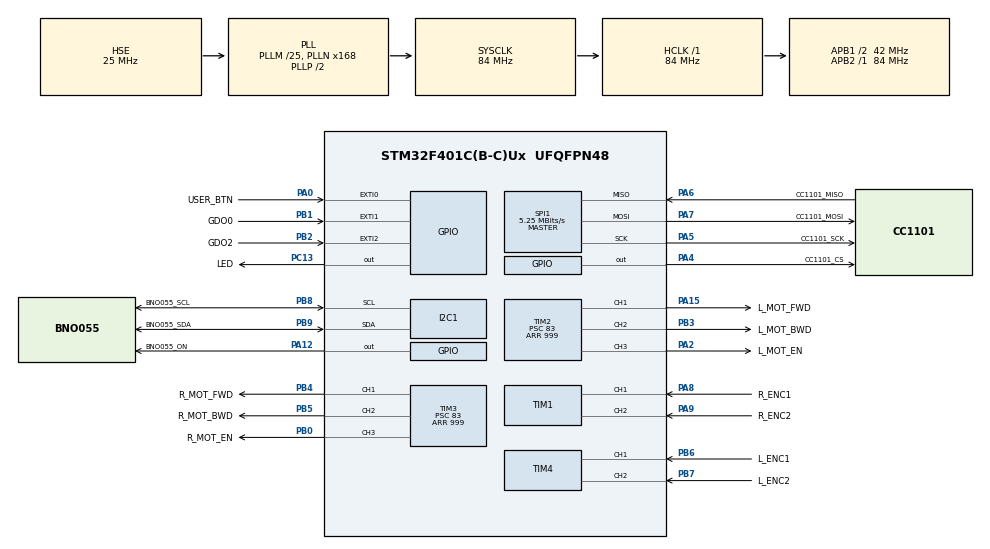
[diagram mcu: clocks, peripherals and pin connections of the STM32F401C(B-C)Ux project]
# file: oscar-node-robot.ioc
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Dma.Request0=SPI1_RX
Dma.Request1=SPI1_TX
Dma.SPI1_RX.0.Direction=DMA_PERIPH_TO_MEMORY
Dma.SPI1_RX.0.FIFOMode=DMA_FIFOMODE_DISABLE
Dma.SPI1_RX.0.Instance=DMA2_Stream0
Dma.SPI1_RX.0.MemDataAlignment=DMA_MDATAALIGN_BYTE
Dma.SPI1_RX.0.MemInc=DMA_MINC_ENABLE
Dma.SPI1_RX.0.Mode=DMA_NORMAL
Dma.SPI1_RX.0.PeriphDataAlignment=DMA_PDATAALIGN_BYTE
Dma.SPI1_RX.0.PeriphInc=DMA_PINC_DISABLE
Dma.SPI1_RX.0.Priority=DMA_PRIORITY_LOW
Dma.SPI1_TX.1.Direction=DMA_MEMORY_TO_PERIPH
Dma.SPI1_TX.1.FIFOMode=DMA_FIFOMODE_DISABLE
Dma.SPI1_TX.1.Instance=DMA2_Stream3
Dma.SPI1_TX.1.MemDataAlignment=DMA_MDATAALIGN_BYTE
Dma.SPI1_TX.1.MemInc=DMA_MINC_ENABLE
Dma.SPI1_TX.1.Mode=DMA_NORMAL
Dma.SPI1_TX.1.PeriphDataAlignment=DMA_PDATAALIGN_BYTE
Dma.SPI1_TX.1.PeriphInc=DMA_PINC_DISABLE
Dma.SPI1_TX.1.Priority=DMA_PRIORITY_LOW
Mcu.Family=STM32F4
Mcu.Name=STM32F401C(B-C)Ux
Mcu.Package=UFQFPN48
NVIC.DMA2_Stream0_IRQn=true\:0\:0\:false\:false\:true\:false\:true\:true
NVIC.DMA2_Stream3_IRQn=true\:0\:0\:false\:false\:true\:false\:true\:true
NVIC.EXTI0_IRQn=true\:0\:0\:false\:false\:true\:true\:true\:true
NVIC.EXTI1_IRQn=true\:0\:0\:false\:false\:true\:true\:true\:true
NVIC.EXTI2_IRQn=true\:0\:0\:false\:false\:true\:true\:true\:true
NVIC.PriorityGroup=NVIC_PRIORITYGROUP_4
PA0-WKUP.GPIO_Label=USER_BTN
PA0-WKUP.Signal=GPXTI0
PA12.GPIO_Label=BNO055_ON
PA12.Signal=GPIO_Output
PA13.Mode=Serial_Wire
PA13.Signal=SYS_JTMS-SWDIO
PA14.Mode=Serial_Wire
PA14.Signal=SYS_JTCK-SWCLK
PA15.GPIO_Label=L_MOT_FWD
PA15.Signal=S_TIM2_CH1_ETR
PA2.GPIO_Label=L_MOT_EN
PA2.Signal=S_TIM2_CH3
PA4.GPIO_Label=CC1101_CS
PA4.Signal=GPIO_Output
PA5.GPIO_Label=CC1101_SCK
PA5.Mode=Full_Duplex_Master
PA5.Signal=SPI1_SCK
PA6.GPIO_Label=CC1101_MISO
PA6.Mode=Full_Duplex_Master
PA6.Signal=SPI1_MISO
PA7.GPIO_Label=CC1101_MOSI
PA7.Mode=Full_Duplex_Master
PA7.Signal=SPI1_MOSI
PA8.GPIO_Label=R_ENC1
PA8.Signal=S_TIM1_CH1
PA9.GPIO_Label=R_ENC2
PA9.Signal=S_TIM1_CH2
PB0.GPIO_Label=R_MOT_EN
PB0.Signal=S_TIM3_CH3
PB1.GPIO_Label=GDO0
PB1.Signal=GPXTI1
PB2.GPIO_Label=GDO2
PB2.Signal=GPXTI2
PB3.GPIO_Label=L_MOT_BWD
PB3.Signal=S_TIM2_CH2
PB4.GPIO_Label=R_MOT_FWD
PB4.Signal=S_TIM3_CH1
PB5.GPIO_Label=R_MOT_BWD
PB5.Signal=S_TIM3_CH2
PB6.GPIO_Label=L_ENC1
PB6.Signal=S_TIM4_CH1
PB7.GPIO_Label=L_ENC2
PB7.Signal=S_TIM4_CH2
PB8.GPIO_Label=BNO055_SCL
PB8.Mode=I2C
PB8.Signal=I2C1_SCL
PB9.GPIO_Label=BNO055_SDA
PB9.Mode=I2C
PB9.Signal=I2C1_SDA
PC13-ANTI_TAMP.GPIO_Label=LED
PC13-ANTI_TAMP.PinState=GPIO_PIN_SET
PC13-ANTI_TAMP.Signal=GPIO_Output
PH0\ -\ OSC_IN.Mode=HSE-External-Oscillator
PH0\ -\ OSC_IN.Signal=RCC_OSC_IN
PH1\ -\ OSC_OUT.Mode=HSE-External-Oscillator
PH1\ -\ OSC_OUT.Signal=RCC_OSC_OUT
ProjectManager.HeapSize=0x200
ProjectManager.StackSize=0x400
ProjectManager.TargetToolchain=CMake
RCC.48MHZClocksFreq_Value=42000000
RCC.AHBFreq_Value=84000000
RCC.APB1CLKDivider=RCC_HCLK_DIV2
RCC.APB1Freq_Value=42000000
RCC.APB1TimFreq_Value=84000000
RCC.APB2Freq_Value=84000000
RCC.APB2TimFreq_Value=84000000
RCC.CortexFreq_Value=84000000
RCC.HCLKFreq_Value=84000000
RCC.HSE_VALUE=25000000
RCC.HSI_VALUE=16000000
RCC.LSE_VALUE=32768
RCC.PLLM=25
RCC.PLLN=168
RCC.PLLSourceVirtual=RCC_PLLSOURCE_HSE
RCC.SYSCLKFreq_VALUE=84000000
RCC.SYSCLKSource=RCC_SYSCLKSOURCE_PLLCLK
RCC.VCOOutputFreq_Value=168000000
SH.S_TIM1_CH1.0=TIM1_CH1,Encoder_Interface
SH.S_TIM1_CH2.0=TIM1_CH2,Encoder_Interface
SH.S_TIM2_CH1_ETR.0=TIM2_CH1,PWM Generation1 CH1
SH.S_TIM2_CH2.0=TIM2_CH2,PWM Generation2 CH2
SH.S_TIM2_CH3.0=TIM2_CH3,PWM Generation3 CH3
SH.S_TIM3_CH1.0=TIM3_CH1,PWM Generation1 CH1
SH.S_TIM3_CH2.0=TIM3_CH2,PWM Generation2 CH2
SH.S_TIM3_CH3.0=TIM3_CH3,PWM Generation3 CH3
SH.S_TIM4_CH1.0=TIM4_CH1,Encoder_Interface
SH.S_TIM4_CH2.0=TIM4_CH2,Encoder_Interface
SPI1.BaudRatePrescaler=SPI_BAUDRATEPRESCALER_16
SPI1.CalculateBaudRate=5.25 MBits/s
SPI1.Direction=SPI_DIRECTION_2LINES
SPI1.Mode=SPI_MODE_MASTER
SPI1.VirtualType=VM_MASTER
TIM2.AutoReloadPreload=TIM_AUTORELOAD_PRELOAD_ENABLE
TIM2.Channel-PWM\ Generation1\ CH1=TIM_CHANNEL_1
TIM2.Channel-PWM\ Generation2\ CH2=TIM_CHANNEL_2
TIM2.Channel-PWM\ Generation3\ CH3=TIM_CHANNEL_3
TIM2.Period=999
TIM2.Prescaler=83
TIM2.Pulse-PWM\ Generation1\ CH1=0
TIM2.Pulse-PWM\ Generation3\ CH3=0
TIM3.AutoReloadPreload=TIM_AUTORELOAD_PRELOAD_ENABLE
TIM3.Channel-PWM\ Generation1\ CH1=TIM_CHANNEL_1
TIM3.Channel-PWM\ Generation2\ CH2=TIM_CHANNEL_2
TIM3.Channel-PWM\ Generation3\ CH3=TIM_CHANNEL_3
TIM3.Period=999
TIM3.Prescaler=83
VP_TIM2_VS_ClockSourceINT.Mode=Internal
VP_TIM3_VS_ClockSourceINT.Mode=Internal
board=custom

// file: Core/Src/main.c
/* USER CODE BEGIN Header */
/**
  ******************************************************************************
  * @file           : main.c
  * @brief          : Main program body
  ******************************************************************************
  * @attention
  *
  * Copyright (c) 2026 STMicroelectronics.
  * All rights reserved.
  *
  * This software is licensed under terms that can be found in the LICENSE file
  * in the root directory of this software component.
  * If no LICENSE file comes with this software, it is provided AS-IS.
  *
  ******************************************************************************
  */
/* USER CODE END Header */
#include "main.h"
#include "dma.h"
#include "i2c.h"
#include "spi.h"
#include "tim.h"
#include "gpio.h"

/* USER CODE BEGIN Includes */
#include "robot_app.h"
/* USER CODE END Includes */

void SystemClock_Config(void);

int main(void)
{

  /* MCU Configuration--------------------------------------------------------*/

  /* Reset of all peripherals, Initializes the Flash interface and the Systick. */
  HAL_Init();

  /* Configure the system clock */
  SystemClock_Config();

  /* USER CODE BEGIN SysInit */
  RobotApp_EnableCycleCounter();
  /* USER CODE END SysInit */

  /* Initialize all configured peripherals */
  MX_GPIO_Init();
  MX_DMA_Init();
  MX_SPI1_Init();
  MX_TIM2_Init();
  MX_TIM3_Init();
  MX_TIM4_Init();
  MX_TIM1_Init();
  MX_I2C1_Init();
  /* USER CODE BEGIN 2 */
  RobotApp_Init();
  /* USER CODE END 2 */

  /* Infinite loop */
  /* USER CODE BEGIN WHILE */
  while (1)
  {
    RobotApp_Tick();

    /* USER CODE END WHILE */

  }
}

void SystemClock_Config(void)
{
  RCC_OscInitTypeDef RCC_OscInitStruct = {0};
  RCC_ClkInitTypeDef RCC_ClkInitStruct = {0};

  /** Configure the main internal regulator output voltage
  */
  __HAL_RCC_PWR_CLK_ENABLE();
  __HAL_PWR_VOLTAGESCALING_CONFIG(PWR_REGULATOR_VOLTAGE_SCALE2);

  /** Initializes the RCC Oscillators according to the specified parameters
  * in the RCC_OscInitTypeDef structure.
  */
  RCC_OscInitStruct.OscillatorType = RCC_OSCILLATORTYPE_HSE;
  RCC_OscInitStruct.HSEState = RCC_HSE_ON;
  RCC_OscInitStruct.PLL.PLLState = RCC_PLL_ON;
  RCC_OscInitStruct.PLL.PLLSource = RCC_PLLSOURCE_HSE;
  RCC_OscInitStruct.PLL.PLLM = 25;
  RCC_OscInitStruct.PLL.PLLN = 168;
  RCC_OscInitStruct.PLL.PLLP = RCC_PLLP_DIV2;
  RCC_OscInitStruct.PLL.PLLQ = 4;
  if (HAL_RCC_OscConfig(&RCC_OscInitStruct) != HAL_OK)
  {
    Error_Handler();
  }

  /** Initializes the CPU, AHB and APB buses clocks
  */
  RCC_ClkInitStruct.ClockType = RCC_CLOCKTYPE_HCLK|RCC_CLOCKTYPE_SYSCLK
                              |RCC_CLOCKTYPE_PCLK1|RCC_CLOCKTYPE_PCLK2;
  RCC_ClkInitStruct.SYSCLKSource = RCC_SYSCLKSOURCE_PLLCLK;
  RCC_ClkInitStruct.AHBCLKDivider = RCC_SYSCLK_DIV1;
  RCC_ClkInitStruct.APB1CLKDivider = RCC_HCLK_DIV2;
  RCC_ClkInitStruct.APB2CLKDivider = RCC_HCLK_DIV1;

  if (HAL_RCC_ClockConfig(&RCC_ClkInitStruct, FLASH_LATENCY_2) != HAL_OK)
  {
    Error_Handler();
  }
}

/* USER CODE BEGIN 4 */
void HAL_GPIO_EXTI_Callback(uint16_t GPIO_Pin)
{
  RobotApp_OnGpioExti(GPIO_Pin);
}
/* USER CODE END 4 */

void Error_Handler(void)
{
  __disable_irq();
  while (1)
  {
  }
}
